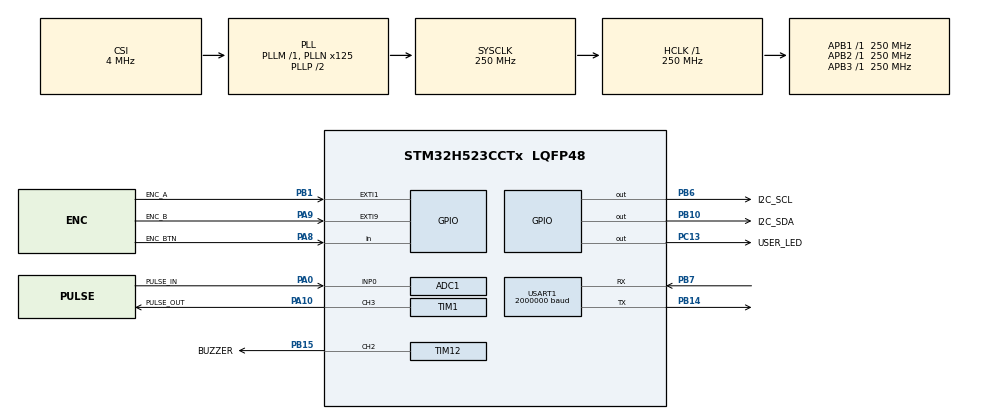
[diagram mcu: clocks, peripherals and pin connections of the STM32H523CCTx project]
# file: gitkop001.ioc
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ADC1.AWD1FilteringConfig=ADC_AWD_FILTERING_4SAMPLES
ADC1.AWD1HighThreshold=4095
ADC1.AWD1ITMode=ENABLE
ADC1.AWD1LowThreshold=2500
ADC1.Channel-1\#ChannelRegularConversion=ADC_CHANNEL_0
ADC1.ContinuousConvMode=ENABLE
ADC1.DMAContinuousRequests=ENABLE
ADC1.EnableAnalogWatchDog1=true
ADC1.ExternalTrigConv=ADC_SOFTWARE_START
ADC1.ExternalTrigConvEdge=ADC_EXTERNALTRIGCONVEDGE_NONE
ADC1.Mode=ADC_MODE_INDEPENDENT
ADC1.MonitoredBy-1\#ChannelRegularConversion=__NULL
ADC1.NbrOfConversion=1
ADC1.NbrOfConversionFlag=1
ADC1.OffsetNumber-1\#ChannelRegularConversion=ADC_OFFSET_NONE
ADC1.Overrun=ADC_OVR_DATA_OVERWRITTEN
ADC1.OversamplingMode=DISABLE
ADC1.Rank-1\#ChannelRegularConversion=1
ADC1.SamplingTime-1\#ChannelRegularConversion=ADC_SAMPLETIME_2CYCLES_5
ADC1.master=1
BOOTPATH.BootPathName=LEGACY
BOOTPATH.UserSelectedBootPath=LEGACY
CORTEX_M33_NS.userName=CORTEX_M33
GPDMA1.CIRCULARMODE_GPDMACH5=ENABLE
GPDMA1.DESTDATAWIDTH_GPDMACH5=DMA_DEST_DATAWIDTH_HALFWORD
GPDMA1.DESTINC_GPDMACH5=DMA_DINC_INCREMENTED
GPDMA1.IPHANDLE_GPDMACH5-SIMPLEREQUEST_GPDMACH5=__NULL
GPDMA1.PRIORITY_LL_CIRCULAR_GPDMACH5=DMA_HIGH_PRIORITY
GPDMA1.REQUEST_GPDMACH5=GPDMA1_REQUEST_ADC1
GPDMA1.SRCDATAWIDTH_GPDMACH5=DMA_SRC_DATAWIDTH_HALFWORD
GPDMA1.SRCINC_GPDMACH5=DMA_SINC_FIXED
GPDMA1.TRANSFEREVENTMODE_LL_CIRCULAR_GPDMACH5=DMA_TCEM_LAST_LL_ITEM_TRANSFER
Mcu.Family=STM32H5
Mcu.Name=STM32H523CCTx
Mcu.Package=LQFP48
NVIC.ADC1_IRQn=true\:0\:0\:false\:false\:true\:true\:true\:true
NVIC.PriorityGroup=NVIC_PRIORITYGROUP_4
NVIC.TIM1_UP_IRQn=true\:0\:0\:false\:false\:true\:true\:true\:true
PA0.GPIO_Label=PULSE_IN
PA0.Signal=ADCx_INP0
PA10.GPIO_Label=PULSE_OUT
PA10.GPIO_Speed=GPIO_SPEED_FREQ_VERY_HIGH
PA10.Signal=S_TIM1_CH3
PA8.GPIO_Label=ENC_BTN
PA8.Signal=GPIO_Input
PA9.GPIO_Label=ENC_B
PA9.GPIO_ModeDefaultEXTI=GPIO_MODE_IT_RISING_FALLING
PA9.GPIO_PuPd=GPIO_PULLUP
PA9.Signal=GPXTI9
PB1.GPIO_Label=ENC_A
PB1.GPIO_ModeDefaultEXTI=GPIO_MODE_IT_RISING_FALLING
PB1.GPIO_PuPd=GPIO_PULLUP
PB1.Signal=GPXTI1
PB10.GPIO_Label=I2C_SDA
PB10.GPIO_ModeDefaultOutputPP=GPIO_MODE_OUTPUT_OD
PB10.GPIO_PuPd=GPIO_NOPULL
PB10.GPIO_Speed=GPIO_SPEED_FREQ_VERY_HIGH
PB10.Signal=GPIO_Output
PB14.Mode=Asynchronous
PB14.Signal=USART1_TX
PB15.GPIO_Label=BUZZER
PB15.Signal=S_TIM12_CH2
PB6.GPIO_Label=I2C_SCL
PB6.GPIO_ModeDefaultOutputPP=GPIO_MODE_OUTPUT_OD
PB6.GPIO_PuPd=GPIO_NOPULL
PB6.GPIO_Speed=GPIO_SPEED_FREQ_VERY_HIGH
PB6.Signal=GPIO_Output
PB7.Mode=Asynchronous
PB7.Signal=USART1_RX
PC13.GPIO_Label=USER_LED
PC13.Signal=GPIO_Output
PC14-OSC32_IN(OSC32_IN).Mode=LSE-External-Oscillator
PC14-OSC32_IN(OSC32_IN).Signal=RCC_OSC32_IN
PC15-OSC32_OUT(OSC32_OUT).Mode=LSE-External-Oscillator
PC15-OSC32_OUT(OSC32_OUT).Signal=RCC_OSC32_OUT
PH0-OSC_IN(PH0).Mode=HSE-External-Oscillator
PH0-OSC_IN(PH0).Signal=RCC_OSC_IN
PH1-OSC_OUT(PH1).Mode=HSE-External-Oscillator
PH1-OSC_OUT(PH1).Signal=RCC_OSC_OUT
ProjectManager.HeapSize=0x200
ProjectManager.StackSize=0x400
ProjectManager.TargetToolchain=CMake
RCC.ADCFreq_Value=250000000
RCC.AHBFreq_Value=250000000
RCC.APB1Freq_Value=250000000
RCC.APB1TimFreq_Value=250000000
RCC.APB2Freq_Value=250000000
RCC.APB2TimFreq_Value=250000000
RCC.APB3Freq_Value=250000000
RCC.CSI_VALUE=4000000
RCC.CortexFreq_Value=250000000
RCC.EPOD_VALUE=4000000
RCC.HCLKFreq_Value=250000000
RCC.HSE_VALUE=8000000
RCC.HSI48_VALUE=48000000
RCC.HSIDiv=RCC_HSI_DIV1
RCC.HSI_VALUE=64000000
RCC.LSIRC_VALUE=32000
RCC.PLL2FRACN=0
RCC.PLL3FRACN=5120
RCC.PLL3M=4
RCC.PLL3N=15
RCC.PLL3Source=RCC_PLL3_SOURCE_HSI
RCC.PLLFRACN=0
RCC.PLLN=125
RCC.PWR_Regulator_Voltage_Scale=PWR_REGULATOR_VOLTAGE_SCALE0
RCC.SPI3CLockSelection=RCC_SPI3CLKSOURCE_CLKP
RCC.SYSCLKFreq_VALUE=250000000
RCC.SYSCLKSource=RCC_SYSCLKSOURCE_PLLCLK
RCC.USBFreq_Value=48000000
RCC.VCOOutputFreq_Value=500000000
SH.ADCx_INP0.0=ADC1_INP0,IN0-Single-Ended
SH.S_TIM12_CH2.0=TIM12_CH2,PWM Generation2 CH2
SH.S_TIM1_CH3.0=TIM1_CH3,PWM Generation3 CH3
TIM1.Channel-PWM\ Generation3\ CH3=TIM_CHANNEL_3
TIM1.PeriodNoDither=50749
TIM1.Prescaler=4
TIM1.PulseNoDither_3=750
TIM12.AutoReloadPreload=TIM_AUTORELOAD_PRELOAD_ENABLE
TIM12.Channel-PWM\ Generation2\ CH2=TIM_CHANNEL_2
TIM12.PeriodNoDither=999
TIM12.Prescaler=249
TIM12.PulseNoDither_2=0
USART1.BaudRate=2000000
USART1.VirtualMode-Asynchronous=VM_ASYNC
VP_BOOTPATH_VS_BOOTPATH.Mode=BP_Activate
VP_CORTEX_M33_NS_VS_Hclk.Mode=Hclk_Mode
VP_GPDMA1_VS_GPDMACH5.Mode=SIMPLEREQUEST_GPDMACH5
VP_ICACHE_VS_ICACHE.Mode=DefaultMode
VP_MEMORYMAP_VS_MEMORYMAP.Mode=CurAppReg
VP_PWR_VS_LPOM.Mode=PowerOptimisation
VP_PWR_VS_SECSignals.Mode=Security/Privilege
board=custom

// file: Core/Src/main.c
/* USER CODE BEGIN Header */
/**
  ******************************************************************************
  * @file           : main.c
  * @brief          : Main program body
  ******************************************************************************
  * @attention
  *
  * Copyright (c) 2025 STMicroelectronics.
  * All rights reserved.
  *
  * This software is licensed under terms that can be found in the LICENSE file
  * in the root directory of this software component.
  * If no LICENSE file comes with this software, it is provided AS-IS.
  *
  ******************************************************************************
  */
/* USER CODE END Header */
#include "main.h"
#include "adc.h"
#include "gpdma.h"
#include "icache.h"
#include "tim.h"
#include "usart.h"
#include "gpio.h"

/* USER CODE BEGIN Includes */
#include "GitKop.h"
/* USER CODE END Includes */

void SystemClock_Config(void);

int main(void)
{

  /* MCU Configuration--------------------------------------------------------*/

  /* Reset of all peripherals, Initializes the Flash interface and the Systick. */
  HAL_Init();

  /* Configure the system clock */
  SystemClock_Config();

  /* Initialize all configured peripherals */
  MX_GPIO_Init();
  MX_GPDMA1_Init();
  MX_ADC1_Init();
  MX_TIM12_Init();
  MX_USART1_UART_Init();
  MX_ICACHE_Init();
  MX_TIM1_Init();
  /* USER CODE BEGIN 2 */

  GitKop_Init();

  /* USER CODE END 2 */

  /* Infinite loop */
  while (1)
  {

  }
}

void SystemClock_Config(void)
{
  RCC_OscInitTypeDef RCC_OscInitStruct = {0};
  RCC_ClkInitTypeDef RCC_ClkInitStruct = {0};

  /** Configure the main internal regulator output voltage
  */
  __HAL_PWR_VOLTAGESCALING_CONFIG(PWR_REGULATOR_VOLTAGE_SCALE0);

  while(!__HAL_PWR_GET_FLAG(PWR_FLAG_VOSRDY)) {}

  /** Initializes the RCC Oscillators according to the specified parameters
  * in the RCC_OscInitTypeDef structure.
  */
  RCC_OscInitStruct.OscillatorType = RCC_OSCILLATORTYPE_CSI;
  RCC_OscInitStruct.CSIState = RCC_CSI_ON;
  RCC_OscInitStruct.CSICalibrationValue = RCC_CSICALIBRATION_DEFAULT;
  RCC_OscInitStruct.PLL.PLLState = RCC_PLL_ON;
  RCC_OscInitStruct.PLL.PLLSource = RCC_PLL1_SOURCE_CSI;
  RCC_OscInitStruct.PLL.PLLM = 1;
  RCC_OscInitStruct.PLL.PLLN = 125;
  RCC_OscInitStruct.PLL.PLLP = 2;
  RCC_OscInitStruct.PLL.PLLQ = 2;
  RCC_OscInitStruct.PLL.PLLR = 2;
  RCC_OscInitStruct.PLL.PLLRGE = RCC_PLL1_VCIRANGE_2;
  RCC_OscInitStruct.PLL.PLLVCOSEL = RCC_PLL1_VCORANGE_WIDE;
  RCC_OscInitStruct.PLL.PLLFRACN = 0;
  if (HAL_RCC_OscConfig(&RCC_OscInitStruct) != HAL_OK)
  {
    Error_Handler();
  }

  /** Initializes the CPU, AHB and APB buses clocks
  */
  RCC_ClkInitStruct.ClockType = RCC_CLOCKTYPE_HCLK|RCC_CLOCKTYPE_SYSCLK
                              |RCC_CLOCKTYPE_PCLK1|RCC_CLOCKTYPE_PCLK2
                              |RCC_CLOCKTYPE_PCLK3;
  RCC_ClkInitStruct.SYSCLKSource = RCC_SYSCLKSOURCE_PLLCLK;
  RCC_ClkInitStruct.AHBCLKDivider = RCC_SYSCLK_DIV1;
  RCC_ClkInitStruct.APB1CLKDivider = RCC_HCLK_DIV1;
  RCC_ClkInitStruct.APB2CLKDivider = RCC_HCLK_DIV1;
  RCC_ClkInitStruct.APB3CLKDivider = RCC_HCLK_DIV1;

  if (HAL_RCC_ClockConfig(&RCC_ClkInitStruct, FLASH_LATENCY_5) != HAL_OK)
  {
    Error_Handler();
  }

  /** Configure the programming delay
  */
  __HAL_FLASH_SET_PROGRAM_DELAY(FLASH_PROGRAMMING_DELAY_2);
}

void Error_Handler(void)
{
  /* USER CODE BEGIN Error_Handler_Debug */
  /* User can add his own implementation to report the HAL error return state */
  __disable_irq();
    printf("error");
  while (1)
  {
  }
  /* USER CODE END Error_Handler_Debug */
}
#ifdef USE_FULL_ASSERT
/**
  * @brief  Reports the name of the source file and the source line number
  *         where the assert_param error has occurred.
  * @param  file: pointer to the source file name
  * @param  line: assert_param error line source number
  * @retval None
  */
void assert_failed(uint8_t *file, uint32_t line)
{
  /* USER CODE BEGIN 6 */
  /* User can add his own implementation to report the file name and line number,
     ex: printf("Wrong parameters value: file %s on line %d\r\n", file, line) */
    printf("Wrong parameters value: file %s on line %ld\r\n", file, line);
  /* USER CODE END 6 */
}
#endif /* USE_FULL_ASSERT */
